# CY8C4248AZI_L485 register map
File version: 0.1
PSoC 4200L
Registers are 32-bit, read-write, no defined reset value unless marked. A register's access mark holds for its fields unless they carry their own. Offsets are from the block's base; lines under a group give offsets from that group; [hi:lo] are bit positions; {n}, {i} and the like mark numbered series; 'fields as' and 'values as' point back to an identical list; <NAME> marks a mode.

## Memory map
0x00000000 Timer
0x00000000 ADC — Sequencing SAR ADC
0x00000000 PWM_2
0x00000000 CAN
0x00000000 DMAC — DMAC Registers
0x00000000 SPI — Serial Communication Block
0x00000000 PWM_0
0x00000000 PWM_1
0x00000000 UART — Serial Communication Block
0x00000000 HumTemp_I2C — Serial Communication Block
0x00000000 Comp_0 — Low Power Comparator
0x00000000 Comp_1 — Low Power Comparator
0x00000000 ADC_3_Buffer — OpAmp
0x00000000 ADC_2_Buffer — OpAmp
0x00000000 CapSense_IDAC1 — IDAC
0x00000000 CapSense_IDAC2 — IDAC

## Timer
Base 0x00000000
0x40200108 COUNTER — Current counter value
0x4020010C CC — Compare / capture value
0x40200110 CC_BUF — Compare / capture buffer value
0x40200114 PERIOD — Period value
0x40200118 PERIOD_BUF — Period buffer value

## PWM_2
Base 0x00000000
0x40200188 COUNTER — Current counter value
0x4020018C CC — Compare / capture value
0x40200190 CC_BUF — Compare / capture buffer value
0x40200194 PERIOD — Period value
0x40200198 PERIOD_BUF — Period buffer value

## PWM_0
Base 0x00000000
0x402001C8 COUNTER — Current counter value
0x402001CC CC — Compare / capture value
0x402001D0 CC_BUF — Compare / capture buffer value
0x402001D4 PERIOD — Period value
0x402001D8 PERIOD_BUF — Period buffer value

## PWM_1
Base 0x00000000
0x40200208 COUNTER — Current counter value
0x4020020C CC — Compare / capture value
0x40200210 CC_BUF — Compare / capture buffer value
0x40200214 PERIOD — Period value
0x40200218 PERIOD_BUF — Period buffer value

## Comp_0 — Low Power Comparator
Base 0x00000000
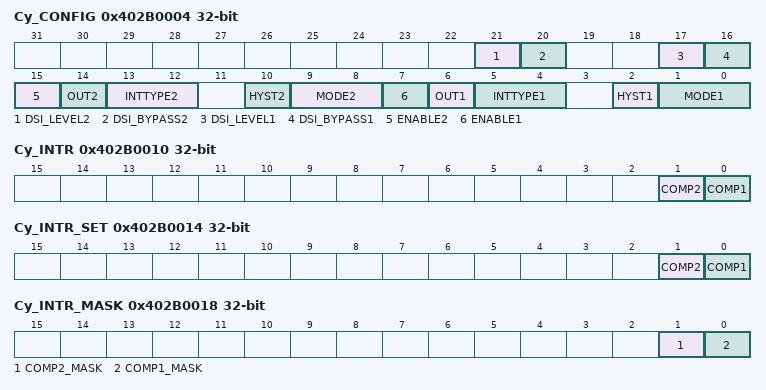
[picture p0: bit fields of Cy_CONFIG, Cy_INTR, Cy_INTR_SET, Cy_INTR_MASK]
0x402B0004 Cy_CONFIG — LPCOMP configuration
  [21] DSI_LEVEL2 — Comparator #2 DSI (trigger) out level
    0=PULSE; 1=LEVEL
  [20] DSI_BYPASS2 — Bypass comparator #2 output synchronization for DSI output
    0=SYNCHRONIZE (Synchronize (level or pulse)); 1=BYPASS (Bypass (output async))
  [17] DSI_LEVEL1 — Comparator #1 DSI (trigger) out level
    0=PULSE; 1=LEVEL
  [16] DSI_BYPASS1 — Bypass comparator #1 output synchronization for DSI output
    values as DSI_BYPASS2
  [15] ENABLE2 — Enable comparator #2
    0=DISABLE (Comparator disabled); 1=ENABLE (Comparator enabled)
  [14] OUT2 ro — Current output value of the comparator #2
  [13:12] INTTYPE2 — Sets which edge will trigger an IRQ for the comparator #2
    0=DISABLE (Disabled); 1=RISING (Rising edge); 2=FALLING (Falling edge); 3=BOTH (Both rising and falling edges)
  [10] HYST2 — Selects hysteresis (10mV) for the comparator #2
    0=ENABLE (Hysteresis enabled); 1=DISABLE (Hysteresis disabled)
  [9:8] MODE2 — Selects speed for the comparator #2
    0=MED (Medium speed); 1=FAST (Fast speed); 2=SLOW (Slow speed)
  [7] ENABLE1 — Enable comparator #1
    values as ENABLE2
  [6] OUT1 ro — Current output value of the comparator
  [5:4] INTTYPE1 — Sets which edge will trigger an IRQ for the comparator #1
    values as INTTYPE2
  [2] HYST1 — Selects hysteresis (10mV) for the comparator #1
    values as HYST2
  [1:0] MODE1 — Selects speed for the comparator #1
    values as MODE2
0x402B0010 Cy_INTR — LPCOMP interrupt
  [1] COMP2 — Comparator #2 Interrupt: hardware sets this interrupt when comparator 0 triggers. Write with '1' to clear bit.
  [0] COMP1 — Comparator #1 Interrupt: hardware sets this interrupt when comparator 0 triggers. Write with '1' to clear bit.
0x402B0014 Cy_INTR_SET — LPCOMP interrupt set register
  [1] COMP2 — Write with '1' to set corresponding bit in interrupt request register.
  [0] COMP1 — Write with '1' to set corresponding bit in interrupt request register.
0x402B0018 Cy_INTR_MASK — LPCOMP interrupt mask
  [1] COMP2_MASK — Mask bit for corresponding bit in interrupt request register.
  [0] COMP1_MASK — Mask bit for corresponding bit in interrupt request register.
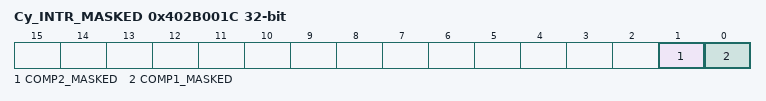
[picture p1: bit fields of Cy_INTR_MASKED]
0x402B001C Cy_INTR_MASKED — LPCOMP interrupt masked
  [1] COMP2_MASKED ro — Logical and of corresponding request and mask bits.
  [0] COMP1_MASKED ro — Logical and of corresponding request and mask bits.
0x402BFF00 Cy_TRIM_A — LPCOMP trim A
0x402BFF04 Cy_TRIM_B — LPCOMP trim B

## Comp_1 — Low Power Comparator
Base 0x00000000
Registers as Comp_0, without Cy_TRIM_A, Cy_TRIM_B; these are added or differ:
0x402BFF08 Cy_TRIM_A — LPCOMP trim A
0x402BFF0C Cy_TRIM_B — LPCOMP trim B
